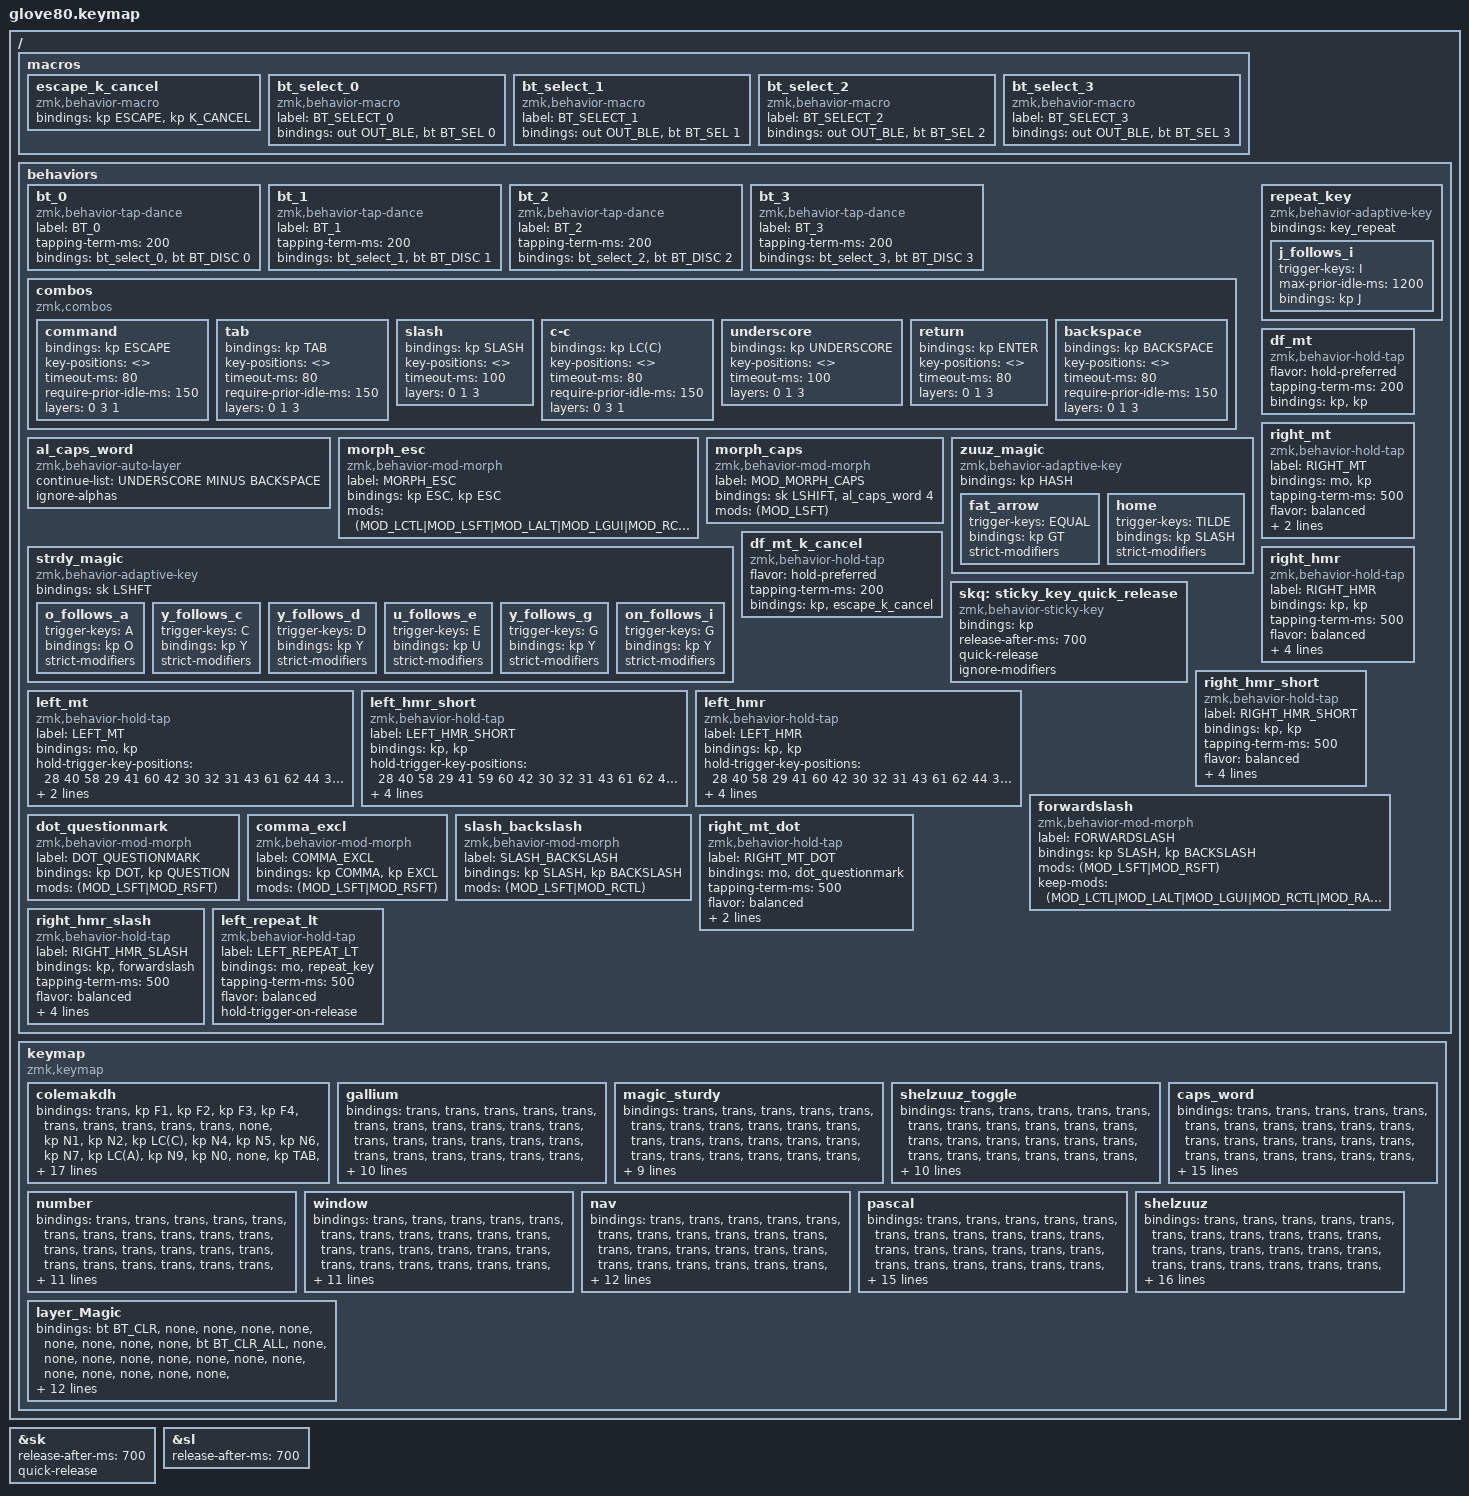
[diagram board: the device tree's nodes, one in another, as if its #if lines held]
#include <behaviors.dtsi>
#include <dt-bindings/zmk/bt.h>
#include <dt-bindings/zmk/keys.h>
#include <dt-bindings/zmk/outputs.h>
#include <dt-bindings/zmk/rgb.h>

#define LAYER_colemakdh 0
#define LAYER_gallium 1
#define LAYER_alt_thumb 2
#define LAYER_alt_thumb_2 3
#define LAYER_alt_top 4
#define LAYER_num_right 5
#define LAYER_another_thumb 6
#define LAYER_another_thumb_2 7
#define LAYER_Nav 10
#define COMBO_REQUIRE_PRIOR_IDLE 160
#define COMBO_TIMEOUT 50
#define QUICK_TAP_MS 180
#define TAPPING_TERM_MS 290
#define PRIOR_IDLE_MS 170
#define LEFT_HAND_KEYS      \
            0  1  2  3  4         \
           10 11 12 13 14 15      \
           22 23 24 25 26 27      \
           34 35 36 37 38 39      \
           46 47 48 49 50 51      \
           64 65 66 67 68
#define                              RIGHT_HAND_KEYS \
                                             5  6  7  8  9 \
                                         16 17 18 19 20 21 \
                                         28 29 30 31 32 33 \
                                         40 41 42 43 44 45 \
                                         58 59 60 61 62 63 \
                                            75 76 77 78 79
#define THUMB_KEYS          \
                          69 52       57 74                \
                           70 53     56 73                 \

&sk {
    release-after-ms = <700>;
    quick-release;
};

&sl { release-after-ms = <700>; };

/ {
    macros {
        escape_k_cancel: escape_k_cancel {
            compatible = "zmk,behavior-macro";
            #binding-cells = <0>;
            bindings = <&kp ESCAPE &kp K_CANCEL>;
        };
    };
};

/ {
    #ifdef BT_DISC_CMD

    behaviors {
        bt_0: bt_0 {
            compatible = "zmk,behavior-tap-dance";
            label = "BT_0";
            #binding-cells = <0>;
            tapping-term-ms = <200>;
            bindings = <&bt_select_0>, <&bt BT_DISC 0>;
        };

        bt_1: bt_1 {
            compatible = "zmk,behavior-tap-dance";
            label = "BT_1";
            #binding-cells = <0>;
            tapping-term-ms = <200>;
            bindings = <&bt_select_1>, <&bt BT_DISC 1>;
        };

        bt_2: bt_2 {
            compatible = "zmk,behavior-tap-dance";
            label = "BT_2";
            #binding-cells = <0>;
            tapping-term-ms = <200>;
            bindings = <&bt_select_2>, <&bt BT_DISC 2>;
        };

        bt_3: bt_3 {
            compatible = "zmk,behavior-tap-dance";
            label = "BT_3";
            #binding-cells = <0>;
            tapping-term-ms = <200>;
            bindings = <&bt_select_3>, <&bt BT_DISC 3>;
        };
    };

    macros {
        bt_select_0: bt_select_0 {
            label = "BT_SELECT_0";
            compatible = "zmk,behavior-macro";
            #binding-cells = <0>;
            bindings = <&out OUT_BLE &bt BT_SEL 0>;
        };

        bt_select_1: bt_select_1 {
            label = "BT_SELECT_1";
            compatible = "zmk,behavior-macro";
            #binding-cells = <0>;
            bindings = <&out OUT_BLE &bt BT_SEL 1>;
        };

        bt_select_2: bt_select_2 {
            label = "BT_SELECT_2";
            compatible = "zmk,behavior-macro";
            #binding-cells = <0>;
            bindings = <&out OUT_BLE &bt BT_SEL 2>;
        };

        bt_select_3: bt_select_3 {
            label = "BT_SELECT_3";
            compatible = "zmk,behavior-macro";
            #binding-cells = <0>;
            bindings = <&out OUT_BLE &bt BT_SEL 3>;
        };
    };

    #else

    macros {
        bt_0: bt_0 {
            label = "BT_0";
            compatible = "zmk,behavior-macro";
            #binding-cells = <0>;
            bindings = <&out OUT_BLE &bt BT_SEL 0>;
        };

        bt_1: bt_1 {
            label = "BT_1";
            compatible = "zmk,behavior-macro";
            #binding-cells = <0>;
            bindings = <&out OUT_BLE &bt BT_SEL 1>;
        };

        bt_2: bt_2 {
            label = "BT_2";
            compatible = "zmk,behavior-macro";
            #binding-cells = <0>;
            bindings = <&out OUT_BLE &bt BT_SEL 2>;
        };

        bt_3: bt_3 {
            label = "BT_3";
            compatible = "zmk,behavior-macro";
            #binding-cells = <0>;
            bindings = <&out OUT_BLE &bt BT_SEL 3>;
        };
    };

    #endif
};

/ {
    behaviors {
        combos {
            compatible = "zmk,combos";

            command {
                bindings = <&kp ESCAPE>;
                key-positions = <>;
                timeout-ms = <80>;
                require-prior-idle-ms = <150>;
            
         layers = <0 3 1>;};

            tab {
                bindings = <&kp TAB>;
                key-positions = <>;
                timeout-ms = <80>;
                require-prior-idle-ms = <150>;
            
         layers = <0 1 3>;};

            slash {
                bindings = <&kp SLASH>;
                key-positions = <>;
                timeout-ms = <100>;
            
         layers = <0 1 3>;};c-c {
         bindings = <&kp LC(C)>;
         key-positions = <>;
         timeout-ms = <80>;
         require-prior-idle-ms = <150>;
         layers = <0 3 1>;};underscore {
         bindings = <&kp UNDERSCORE>;
         key-positions = <>;
         timeout-ms = <100>;
         layers = <0 1 3>;};return {
         bindings = <&kp ENTER>;
         key-positions = <>;
         timeout-ms = <80>;
         layers = <0 1 3>;};backspace {
         bindings = <&kp BACKSPACE>;
         key-positions = <>;
         timeout-ms = <80>;
         require-prior-idle-ms = <150>;
         layers = <0 1 3>;};
        };

		al_caps_word: al_caps_word {
			compatible = "zmk,behavior-auto-layer";
			#binding-cells = <1>;
			continue-list = <UNDERSCORE MINUS BACKSPACE>;
			ignore-alphas;
		};

        morph_esc: morph_esc {
            compatible = "zmk,behavior-mod-morph";
            label = "MORPH_ESC";
            #binding-cells = <0>;
            bindings = <&kp ESC>, <&kp ESC>;
            mods = <(MOD_LCTL|MOD_LSFT|MOD_LALT|MOD_LGUI|MOD_RCTL|MOD_RSFT|MOD_RGUI|MOD_RALT)>;
        };

        morph_caps: morph_caps {
            compatible = "zmk,behavior-mod-morph";
            label = "MOD_MORPH_CAPS";
            #binding-cells = <0>;
            bindings = <&sk LSHIFT>, <&al_caps_word 4>;
            mods = <(MOD_LSFT)>;
        };


		zuuz_magic: zuuz_magic {
			compatible = "zmk,behavior-adaptive-key";
			#binding-cells = <0>;
			bindings = <&kp HASH>;

			fat_arrow {
				trigger-keys = <EQUAL>;
				bindings = <&kp GT>;
				strict-modifiers;
			};

            home {
                trigger-keys = <TILDE>;
                bindings = <&kp SLASH>;
                strict-modifiers;
            };
		};

		strdy_magic: strdy_magic {
			compatible = "zmk,behavior-adaptive-key";
			#binding-cells = <0>;
			bindings = <&sk LSHFT>;

			o_follows_a {
				trigger-keys = <A>;
				bindings = <&kp O>;
				strict-modifiers;
			};

			y_follows_c {
				trigger-keys = <C>;
				bindings = <&kp Y>;
				strict-modifiers;
			};

			y_follows_d {
				trigger-keys = <D>;
				bindings = <&kp Y>;
				strict-modifiers;
			};

			u_follows_e {
				trigger-keys = <E>;
				bindings = <&kp U>;
				strict-modifiers;
			};

			y_follows_g {
				trigger-keys = <G>;
				bindings = <&kp Y>;
				strict-modifiers;
			};

			on_follows_i {
				trigger-keys = <G>;
				bindings = <&kp Y>;
				strict-modifiers;
			};
		};

		repeat_key: repeat_key {
			compatible = "zmk,behavior-adaptive-key";
			#binding-cells = <0>;
			bindings = <&key_repeat>;

			j_follows_i {
				trigger-keys = <I>;
				max-prior-idle-ms = <1200>;
				bindings = <&kp J>;
			};
		};

        df_mt_k_cancel: df_mt_k_cancel {
            compatible = "zmk,behavior-hold-tap";
            #binding-cells = <2>;
            flavor = "hold-preferred";
            tapping-term-ms = <200>;
            bindings = <&kp>, <&escape_k_cancel>;
        };

        df_mt: df_mt {
            compatible = "zmk,behavior-hold-tap";
            #binding-cells = <2>;
            flavor = "hold-preferred";
            tapping-term-ms = <200>;
            bindings = <&kp>, <&kp>;
        };

        skq: sticky_key_quick_release {
            compatible = "zmk,behavior-sticky-key";
            #binding-cells = <1>;
            bindings = <&kp>;
            release-after-ms = <700>;
            quick-release;
            ignore-modifiers;
        };

        left_mt: left_mt {
            compatible = "zmk,behavior-hold-tap";
            label = "LEFT_MT";
            bindings = <&mo>, <&kp>;

            #binding-cells = <2>;
            hold-trigger-key-positions = <28 40 58 29 41 60 42 30 32 31 43 61 62 44 33 45 63 16 17 18 19 20 21 57 73 74 62 75 76 77 78 79 59>;
            tapping-term-ms = <500>;
            flavor = "balanced";
        };

        left_hmr_short: left_hmr_short {
            compatible = "zmk,behavior-hold-tap";
            label = "LEFT_HMR_SHORT";
            bindings = <&kp>, <&kp>;

            #binding-cells = <2>;
            hold-trigger-key-positions = <28 40 58 29 41 59 60 42 30 32 31 43 61 62 44 33 45 63 16 17 18 19 20 21 57 73 74 62 75 76 77 78 79>;
            tapping-term-ms = <500>;
            flavor = "balanced";
            hold-trigger-on-release;
        
         require-prior-idle-ms = <80>;};


        left_hmr: left_hmr {
            compatible = "zmk,behavior-hold-tap";
            label = "LEFT_HMR";
            bindings = <&kp>, <&kp>;

            #binding-cells = <2>;
            hold-trigger-key-positions = <28 40 58 29 41 60 42 30 32 31 43 61 62 44 33 45 63 16 17 18 19 20 21 57 73 74 62 75 76 77 78 79 59>;

            tapping-term-ms = <500>;
            flavor = "balanced";
            require-prior-idle-ms = <135>;
            hold-trigger-on-release;
        };

        right_mt: right_mt {
            compatible = "zmk,behavior-hold-tap";
            label = "RIGHT_MT";
            bindings = <&mo>, <&kp>;

            #binding-cells = <2>;
            tapping-term-ms = <500>;
            flavor = "balanced";
            hold-trigger-key-positions = <27 39 51 50 38 25 26 37 49 48 36 24 23 35 47 34 22 46 10 11 12 13 14 15 52 69 70 46 47 64 65 66 67 68>;
        };

        right_hmr: right_hmr {
            compatible = "zmk,behavior-hold-tap";
            label = "RIGHT_HMR";
            bindings = <&kp>, <&kp>;

            #binding-cells = <2>;
            tapping-term-ms = <500>;
            flavor = "balanced";
            hold-trigger-key-positions = <27 39 51 50 38 25 26 37 49 48 36 24 23 35 47 34 22 46 10 11 12 13 14 15 52 69 70 46 47 64 65 66 67 68>;
            require-prior-idle-ms = <135>;
            hold-trigger-on-release;
        };


        right_hmr_short: right_hmr_short {
            compatible = "zmk,behavior-hold-tap";
            label = "RIGHT_HMR_SHORT";
            bindings = <&kp>, <&kp>;

            #binding-cells = <2>;
            tapping-term-ms = <500>;
            flavor = "balanced";
            hold-trigger-key-positions = <27 39 51 50 38 25 26 37 49 48 36 24 23 35 47 34 22 46 10 11 12 13 14 15 52 69 70 46 47 64 65 66 67 68>;
            hold-trigger-on-release;
        
         require-prior-idle-ms = <80>;};

        forwardslash: forwardslash {
            compatible = "zmk,behavior-mod-morph";
            label = "FORWARDSLASH";
            bindings = <&kp SLASH>, <&kp BACKSLASH>;
            #binding-cells = <0>;
            mods = <(MOD_LSFT|MOD_RSFT)>;
            keep-mods = <(MOD_LCTL|MOD_LALT|MOD_LGUI|MOD_RCTL|MOD_RALT|MOD_RGUI)>;};dot_questionmark: dot_questionmark {
      compatible = "zmk,behavior-mod-morph";
    
         label = "DOT_QUESTIONMARK";
         bindings = <&kp DOT>, <&kp QUESTION>;
         #binding-cells = <0>;
         mods = <(MOD_LSFT|MOD_RSFT)>;};comma_excl: comma_excl {
      compatible = "zmk,behavior-mod-morph";
    
         label = "COMMA_EXCL";
         bindings = <&kp COMMA>, <&kp EXCL>;
         #binding-cells = <0>;
         mods = <(MOD_LSFT|MOD_RSFT)>;};slash_backslash: slash_backslash {
      compatible = "zmk,behavior-mod-morph";
    
         label = "SLASH_BACKSLASH";
         bindings = <&kp SLASH>, <&kp BACKSLASH>;
         #binding-cells = <0>;
         mods = <(MOD_LSFT|MOD_RCTL)>;};right_mt_dot: right_mt_dot {
      compatible = "zmk,behavior-hold-tap";
    
         label = "RIGHT_MT_DOT";
         bindings = <&mo>, <&dot_questionmark>;
         #binding-cells = <2>;
         tapping-term-ms = <500>;
         flavor = "balanced";
         hold-trigger-key-positions = <27 39 51 50 38 25 26 37 49 48 36 24 23 35 47 34 22 46 10 11 12 13 14 15 52 69 70 46 47 64 65 66 67 68>;};right_hmr_slash: right_hmr_slash {
      compatible = "zmk,behavior-hold-tap";
    
         label = "RIGHT_HMR_SLASH";
         bindings = <&kp>, <&forwardslash>;
         #binding-cells = <2>;
         tapping-term-ms = <500>;
         flavor = "balanced";
         hold-trigger-key-positions = <27 39 51 50 38 25 26 37 49 48 36 24 23 35 47 34 22 46 10 11 12 13 14 15 52 69 70 46 47 64 65 66 67 68>;
         require-prior-idle-ms = <150>;
         hold-trigger-on-release;};left_repeat_lt: left_repeat_lt {
      compatible = "zmk,behavior-hold-tap";
    
         label = "LEFT_REPEAT_LT";
         bindings = <&mo>, <&repeat_key>;
         #binding-cells = <2>;
         tapping-term-ms = <500>;
         flavor = "balanced";
         hold-trigger-on-release;};
    };
};

/ {


behaviors {};

behaviors {};

behaviors {};

behaviors {};

behaviors {};

behaviors {};

behaviors {};

behaviors {};

behaviors {};

behaviors {};

behaviors {};

behaviors {};

behaviors {};

behaviors {};

behaviors {};

behaviors {};

behaviors {};

behaviors {};

behaviors {};

behaviors {};

behaviors {};

behaviors {};

behaviors {};

behaviors {};

behaviors {};

behaviors {};

behaviors {};

behaviors {};

behaviors {};

behaviors {};

behaviors {};

behaviors {};

behaviors {};

behaviors {};
keymap {
        compatible = "zmk,keymap";

        colemakdh {
            bindings = <
&trans          &kp F1                &kp F2        &kp F3                  &kp F4                                                                                                                            &trans                    &trans                    &trans             &trans                   &trans
&none           &kp N1                &kp N2        &kp LC(C)               &kp N4                   &kp N5                                                                                           &kp N6  &kp N7                    &kp LC(A)                 &kp N9             &kp N0                   &none
&kp TAB         &kp Q                 &kp W         &kp F                   &kp P                    &kp B                                                                                            &kp J   &kp L                     &kp U                     &kp Y              &kp SINGLE_QUOTE         &forwardslash
&kp BACKSPACE   &left_hmr LEFT_ALT A  &left_mt 8 R  &left_hmr LEFT_SHIFT S  &left_mt 7 T             &kp G                                                                                            &kp M   &right_mt 5 N             &right_hmr RIGHT_SHIFT E  &right_mt 8 I      &right_hmr LEFT_ALT O    &kp MINUS
&kp UNDERSCORE  &left_hmr LGUI Z      &kp X         &kp C                   &left_hmr_short LCTRL D  &kp V   &morph_caps          &kp LCTRL   &kp LG(GRAVE)    &kp LGUI      &kp RCTRL   &morph_caps  &kp K   &right_hmr_short RCTRL H  &comma_excl               &right_mt_dot 6 0  &right_hmr_slash RGUI 0  &kp LS(SEMI)
&mo 10          &none                 &none         &none                   &none                            &left_repeat_lt 7 0  &morph_esc  &kp LEFT_ALT     &kp LEFT_ALT  &kp RETURN  &kp SPACE            &none                     &none                     &none              &none                    &none
>;
        };
gallium {
            bindings = <
&trans  &trans  &trans  &trans  &trans                                                                    &trans  &trans     &trans   &trans            &trans
&trans  &trans  &trans  &trans  &trans  &trans                                                    &trans  &trans  &trans     &trans   &trans            &trans
&trans  &kp B   &kp L   &kp D   &kp C   &kp V                                                     &kp J   &kp Y   &kp O      &kp U    &kp SINGLE_QUOTE  &trans
&trans  &kp N   &kp R   &kp T   &kp S   &kp G                                                     &kp P   &kp H   &kp A      &kp E    &kp I             &trans
&trans  &kp X   &kp Q   &kp M   &kp W   &kp Z   &trans  &trans  &trans    &trans  &trans  &trans  &kp K   &kp F   &kp COMMA  &kp DOT  &kp SEMI          &trans
&trans  &trans  &trans  &trans  &trans          &trans  &trans  &trans    &trans  &trans  &trans          &trans  &trans     &trans   &trans            &trans
>;
        };
magic_sturdy {
            bindings = <
&trans  &trans  &trans  &trans  &trans                                                                    &trans   &trans  &trans  &trans  &trans
&trans  &trans  &trans  &trans  &trans  &trans                                                    &trans  &trans   &trans  &trans  &trans  &trans
&trans  &kp V   &kp M   &kp L   &kp C   &kp P                                                     &kp B   &kp DOT  &kp U   &kp O   &kp Q   &trans
&trans  &kp S   &kp T   &kp R   &kp D   &kp Y                                                     &kp F   &kp N    &kp E   &kp A   &kp I   &trans
&trans  &kp X   &kp K   &kp J   &kp G   &kp W   &trans  &trans  &trans    &trans  &trans  &trans  &kp Z   &kp H    &trans  &trans  &trans  &trans
&trans  &trans  &trans  &trans  &trans          &trans  &trans  &trans    &trans  &trans  &trans          &trans   &trans  &trans  &trans  &trans
>;
        };
shelzuuz_toggle {
         bindings = <
&trans  &trans  &trans        &trans  &trans                                                                    &trans  &trans  &trans         &trans  &trans
&trans  &trans  &trans        &trans  &trans  &trans                                                    &trans  &trans  &trans  &trans         &trans  &trans
&trans  &trans  &trans        &trans  &trans  &trans                                                    &trans  &trans  &trans  &trans         &trans  &trans
&trans  &trans  &left_mt 9 R  &trans  &trans  &trans                                                    &trans  &trans  &trans  &right_mt 9 I  &trans  &trans
&trans  &trans  &trans        &trans  &trans  &trans  &trans  &trans  &trans    &trans  &trans  &trans  &trans  &trans  &trans  &trans         &trans  &trans
&trans  &trans  &trans        &trans  &trans          &trans  &trans  &trans    &trans  &trans  &trans          &trans  &trans  &trans         &trans  &trans
>;};
caps_word {
         bindings = <
&trans  &trans                    &trans            &trans                      &trans                                                                                         &trans                  &trans                        &trans             &trans                     &trans
&trans  &trans                    &trans            &trans                      &trans                 &trans                                                       &trans     &trans                  &trans                        &trans             &trans                     &trans
&trans  &kp LS(Q)                 &kp LS(W)         &kp LS(F)                   &kp LS(P)              &kp LS(B)                                                    &kp LS(J)  &kp LS(L)               &kp LS(U)                     &kp LS(Y)          &trans                     &trans
&trans  &left_hmr LEFT_ALT LS(A)  &left_mt 8 LS(R)  &left_hmr LEFT_SHIFT LS(S)  &left_mt 7 LS(T)       &kp LS(G)                                                    &kp LS(M)  &right_mt 5 LS(N)       &right_hmr RIGHT_SHIFT LS(E)  &right_mt 8 LS(I)  &right_hmr LEFT_ALT LS(O)  &trans
&trans  &kp LS(Z)                 &kp LS(X)         &kp LS(C)                   &left_hmr RCTRL LS(D)  &kp LS(V)  &trans  &trans  &trans    &trans  &trans  &trans  &kp LS(K)  &right_hmr RCTRL LS(H)  &trans                        &trans             &trans                     &trans
&trans  &trans                    &trans            &trans                      &trans                            &trans  &trans  &trans    &trans  &trans  &trans             &trans                  &trans                        &trans             &trans                     &trans
>;};
number {
            bindings = <
&trans  &trans     &trans  &trans  &trans                                                                           &trans  &trans     &trans     &trans        &trans
&trans  &trans     &trans  &trans  &trans  &trans                                                           &trans  &trans  &trans     &trans     &trans        &trans
&trans  &kp FSLH   &kp N9  &kp N8  &kp N7  &kp STAR                                                         &trans  &trans  &trans     &trans     &trans        &trans
&trans  &kp DOT    &kp N3  &kp N2  &kp N1  &kp LS(PLUS)                                                     &trans  &trans  &kp TAB    &kp LCTRL  &kp LEFT_ALT  &trans
&trans  &kp MINUS  &kp N6  &kp N5  &kp N4  &kp LS(PRCNT)  &trans  &trans  &trans    &trans  &trans  &trans  &trans  &trans  &kp COMMA  &kp DOT    &kp LGUI      &trans
&trans  &trans     &trans  &trans  &trans                 &kp N0  &trans  &trans    &trans  &trans  &trans          &trans  &trans     &trans     &trans        &trans
>;
        };
window {
            bindings = <
&trans  &trans       &trans      &trans      &trans                                                                        &trans  &trans     &trans     &trans    &trans
&trans  &trans       &trans      &trans      &trans      &trans                                                    &trans  &trans  &trans     &trans     &trans    &trans
&trans  &trans       &kp RG(N9)  &kp RG(N8)  &kp RG(N7)  &trans                                                    &trans  &trans  &trans     &trans     &trans    &trans
&trans  &trans       &kp RG(N3)  &kp RG(N2)  &kp RG(N1)  &trans                                                    &trans  &trans  &kp E      &kp LCTRL  &kp LALT  &trans
&trans  &kp LG(TAB)  &kp RG(N6)  &kp RG(N5)  &kp RG(N4)  &trans  &trans  &trans  &trans    &trans  &trans  &trans  &trans  &trans  &kp COMMA  &kp DOT    &kp RGUI  &trans
&trans  &trans       &trans      &trans      &trans              &trans  &trans  &trans    &trans  &trans  &trans          &trans  &trans     &trans     &trans    &trans
>;
        };
nav {
            bindings = <
&trans  &trans        &trans     &trans          &trans                                                                      &trans         &trans         &trans     &trans   &trans
&trans  &trans        &trans     &trans          &trans  &trans                                                    &trans    &trans         &trans         &trans     &trans   &trans
&trans  &trans        &trans     &trans          &trans  &trans                                                    &trans    &kp PAGE_DOWN  &kp PG_UP      &kp LC(Y)  &kp TAB  &trans
&trans  &sk LEFT_ALT  &sk LCTRL  &sk LEFT_SHIFT  &none   &trans                                                    &kp LEFT  &kp DOWN       &kp UP_ARROW   &kp RIGHT  &trans   &trans
&trans  &kp LCMD      &trans     &kp LC(C)       &trans  &trans  &trans  &trans  &trans    &trans  &trans  &trans  &trans    &kp LC(LEFT)   &kp LC(RIGHT)  &trans     &trans   &trans
&trans  &trans        &trans     &trans          &trans          &trans  &trans  &trans    &trans  &trans  &trans            &trans         &trans         &trans     &trans   &trans
>;
        };
pascal {
            bindings = <
&trans  &trans     &trans         &trans            &trans                                                                                         &trans                &trans                 &trans      &trans            &trans
&trans  &trans     &trans         &trans            &trans             &trans                                                           &trans     &trans                &trans                 &trans      &trans            &trans
&trans  &kp GRAVE  &kp LESS_THAN  &kp GT            &kp MINUS          &kp PIPE                                                         &kp CARET  &kp LS(LEFT_BRACKET)  &kp LS(RIGHT_BRACKET)  &kp DOLLAR  &kp SINGLE_QUOTE  &trans
&trans  &kp EXCL   &kp STAR       &slash_backslash  &kp EQUAL          &kp AMPERSAND                                                    &kp HASH   &kp LEFT_PARENTHESIS  &kp RIGHT_PARENTHESIS  &kp SEMI    &kp DQT           &trans
&trans  &kp TILDE  &kp PLUS       &kp LEFT_BRACKET  &kp RIGHT_BRACKET  &kp PERCENT    &trans  &trans  &trans    &trans  &trans  &trans  &kp AT     &kp COLON             &kp COMMA              &kp DOT     &trans            &trans
&trans  &trans     &trans         &trans            &trans                            &trans  &trans  &trans    &trans  &trans  &trans             &trans                &trans                 &trans      &trans            &trans
>;
        };
shelzuuz {
         bindings = <
&trans  &trans       &trans          &trans       &trans                                                                                     &trans                &trans                 &trans            &trans             &trans
&trans  &trans       &trans          &trans       &trans         &trans                                                           &trans     &trans                &trans                 &trans            &trans             &trans
&trans  &kp GRAVE    &kp TILDE       &zuuz_magic  &kp AMPERSAND  &kp PIPE                                                         &kp CARET  &kp LEFT_BRACE        &kp RIGHT_BRACE        &kp LEFT_BRACKET  &kp RIGHT_BRACKET  &trans
&trans  &kp EXCL     &kp UNDERSCORE  &kp COLON    &kp EQUAL      &kp DOLLAR                                                       &kp AT     &kp LEFT_PARENTHESIS  &kp RIGHT_PARENTHESIS  &kp UNDERSCORE    &kp SEMICOLON      &trans
&trans  &kp PERCENT  &kp QUESTION    &kp STAR     &kp PLUS       &kp BACKSLASH  &trans  &trans  &trans    &trans  &trans  &trans  &kp SLASH  &kp MINUS             &kp LESS_THAN          &kp GREATER_THAN  &kp DOUBLE_QUOTES  &trans
&trans  &trans       &trans          &trans       &trans                        &trans  &trans  &trans    &trans  &trans  &trans             &trans                &trans                 &trans            &trans             &trans
>;};
layer_Magic {
            bindings = <
&bt BT_CLR   &none            &none            &none            &none                                                                                       &none   &none   &none  &none   &bt BT_CLR_ALL
&none        &none            &none            &none            &none            &none                                                               &none  &none   &none   &none  &none   &none
&none        &rgb_ug RGB_SPI  &rgb_ug RGB_SAI  &rgb_ug RGB_HUI  &rgb_ug RGB_BRI  &rgb_ug RGB_TOG                                                     &none  &tog 1  &none   &none  &none   &none
&bootloader  &rgb_ug RGB_SPD  &rgb_ug RGB_SAD  &rgb_ug RGB_HUD  &rgb_ug RGB_BRD  &rgb_ug RGB_EFF                                                     &none  &none   &none   &none  &none   &bootloader
&sys_reset   &none            &none            &none            &none            &none            &bt_2  &bt_3  &none           &none  &none  &none  &none  &tog 2  &tog 3  &none  &trans  &sys_reset
&none        &none            &none            &none            &none                             &bt_0  &bt_1  &out OUT_USB    &none  &none  &none         &none   &none   &none  &none   &none
>;
        };
    };
};
